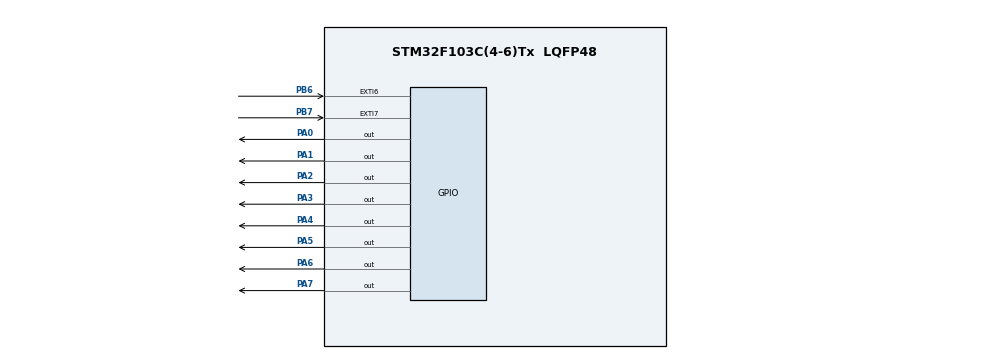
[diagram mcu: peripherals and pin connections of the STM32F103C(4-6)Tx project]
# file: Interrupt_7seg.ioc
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Mcu.Family=STM32F1
Mcu.Name=STM32F103C(4-6)Tx
Mcu.Package=LQFP48
NVIC.EXTI9_5_IRQn=true\:0\:0\:false\:false\:true\:true\:true
NVIC.PriorityGroup=NVIC_PRIORITYGROUP_4
PA0-WKUP.GPIO_Speed=GPIO_SPEED_FREQ_HIGH
PA0-WKUP.Signal=GPIO_Output
PA1.GPIO_Speed=GPIO_SPEED_FREQ_HIGH
PA1.Signal=GPIO_Output
PA2.GPIO_Speed=GPIO_SPEED_FREQ_HIGH
PA2.Signal=GPIO_Output
PA3.GPIO_Speed=GPIO_SPEED_FREQ_HIGH
PA3.Signal=GPIO_Output
PA4.GPIO_Speed=GPIO_SPEED_FREQ_HIGH
PA4.Signal=GPIO_Output
PA5.GPIO_Speed=GPIO_SPEED_FREQ_HIGH
PA5.Signal=GPIO_Output
PA6.GPIO_Speed=GPIO_SPEED_FREQ_HIGH
PA6.Signal=GPIO_Output
PA7.GPIO_Speed=GPIO_SPEED_FREQ_HIGH
PA7.Signal=GPIO_Output
PB6.GPIO_ModeDefaultEXTI=GPIO_MODE_IT_FALLING
PB6.Signal=GPXTI6
PB7.GPIO_ModeDefaultEXTI=GPIO_MODE_IT_FALLING
PB7.Signal=GPXTI7
ProjectManager.HeapSize=0x200
ProjectManager.StackSize=0x400
ProjectManager.TargetToolchain=MDK-ARM V5
RCC.APB1Freq_Value=8000000
RCC.APB2Freq_Value=8000000
VP_SYS_VS_ND.Mode=No_Debug
board=custom

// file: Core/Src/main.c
/* USER CODE BEGIN Header */
/**
  ******************************************************************************
  * @file           : main.c
  * @brief          : Main program body
  ******************************************************************************
  * @attention
  *
  * <h2><center>&copy; Copyright (c) 2021 STMicroelectronics.
  * All rights reserved.</center></h2>
  *
  * This software component is licensed by ST under BSD 3-Clause license,
  * the "License"; You may not use this file except in compliance with the
  * License. You may obtain a copy of the License at:
  *                        opensource.org/licenses/BSD-3-Clause
  *
  ******************************************************************************
  */
/* USER CODE END Header */
#include "main.h"

/* USER CODE BEGIN Includes */
#include "led7seg.h"
/* USER CODE END Includes */

uint8_t count = 0;
void SystemClock_Config(void);
static void MX_GPIO_Init(void);

/* USER CODE BEGIN 0 */
void HAL_GPIO_EXTI_Callback(uint16_t GPIO_Pin)
{
  if(GPIO_Pin == GPIO_PIN_6)
	{
		count++;
		if(count >= 10)
		{
			count = 0;
		}
	}
	if(GPIO_Pin == GPIO_PIN_7)
	{
		if(count == 0)
		{
			count = 9;
		}
		else
		{
			count--;
		}
	}
}
/* USER CODE END 0 */

int main(void)
{

  /* MCU Configuration--------------------------------------------------------*/

  /* Reset of all peripherals, Initializes the Flash interface and the Systick. */
  HAL_Init();

  /* Configure the system clock */
  SystemClock_Config();

  /* Initialize all configured peripherals */
  MX_GPIO_Init();

  /* Infinite loop */
  while (1)
  {
		 LED7_Number(count);
  }
}

void SystemClock_Config(void)
{
  RCC_OscInitTypeDef RCC_OscInitStruct = {0};
  RCC_ClkInitTypeDef RCC_ClkInitStruct = {0};

  /** Initializes the RCC Oscillators according to the specified parameters
  * in the RCC_OscInitTypeDef structure.
  */
  RCC_OscInitStruct.OscillatorType = RCC_OSCILLATORTYPE_HSI;
  RCC_OscInitStruct.HSIState = RCC_HSI_ON;
  RCC_OscInitStruct.HSICalibrationValue = RCC_HSICALIBRATION_DEFAULT;
  RCC_OscInitStruct.PLL.PLLState = RCC_PLL_NONE;
  if (HAL_RCC_OscConfig(&RCC_OscInitStruct) != HAL_OK)
  {
    Error_Handler();
  }
  /** Initializes the CPU, AHB and APB buses clocks
  */
  RCC_ClkInitStruct.ClockType = RCC_CLOCKTYPE_HCLK|RCC_CLOCKTYPE_SYSCLK
                              |RCC_CLOCKTYPE_PCLK1|RCC_CLOCKTYPE_PCLK2;
  RCC_ClkInitStruct.SYSCLKSource = RCC_SYSCLKSOURCE_HSI;
  RCC_ClkInitStruct.AHBCLKDivider = RCC_SYSCLK_DIV1;
  RCC_ClkInitStruct.APB1CLKDivider = RCC_HCLK_DIV1;
  RCC_ClkInitStruct.APB2CLKDivider = RCC_HCLK_DIV1;

  if (HAL_RCC_ClockConfig(&RCC_ClkInitStruct, FLASH_LATENCY_0) != HAL_OK)
  {
    Error_Handler();
  }
}

static void MX_GPIO_Init(void)
{
  GPIO_InitTypeDef GPIO_InitStruct = {0};

  /* GPIO Ports Clock Enable */
  __HAL_RCC_GPIOA_CLK_ENABLE();
  __HAL_RCC_GPIOB_CLK_ENABLE();

  /*Configure GPIO pin Output Level */
  HAL_GPIO_WritePin(GPIOA, GPIO_PIN_0|GPIO_PIN_1|GPIO_PIN_2|GPIO_PIN_3
                          |GPIO_PIN_4|GPIO_PIN_5|GPIO_PIN_6|GPIO_PIN_7, GPIO_PIN_RESET);

  /*Configure GPIO pins : PA0 PA1 PA2 PA3
                           PA4 PA5 PA6 PA7 */
  GPIO_InitStruct.Pin = GPIO_PIN_0|GPIO_PIN_1|GPIO_PIN_2|GPIO_PIN_3
                          |GPIO_PIN_4|GPIO_PIN_5|GPIO_PIN_6|GPIO_PIN_7;
  GPIO_InitStruct.Mode = GPIO_MODE_OUTPUT_PP;
  GPIO_InitStruct.Pull = GPIO_NOPULL;
  GPIO_InitStruct.Speed = GPIO_SPEED_FREQ_HIGH;
  HAL_GPIO_Init(GPIOA, &GPIO_InitStruct);

  /*Configure GPIO pins : PB6 PB7 */
  GPIO_InitStruct.Pin = GPIO_PIN_6|GPIO_PIN_7;
  GPIO_InitStruct.Mode = GPIO_MODE_IT_FALLING;
  GPIO_InitStruct.Pull = GPIO_NOPULL;
  HAL_GPIO_Init(GPIOB, &GPIO_InitStruct);

  /* EXTI interrupt init*/
  HAL_NVIC_SetPriority(EXTI9_5_IRQn, 0, 0);
  HAL_NVIC_EnableIRQ(EXTI9_5_IRQn);

}

void Error_Handler(void)
{
  __disable_irq();
  while (1)
  {
  }
}

/************************ (C) COPYRIGHT STMicroelectronics *****END OF FILE****/
